# STM32N655 register map
File version: 1.0
CPU: CM55 r0p1, little endian, no MPU, FPU, vendor SysTick, 8 interrupt priority bits
Registers are 32-bit, read-write, reset 0x0 unless marked. A register's access mark holds for its fields unless they carry their own. Offsets are from the block's base; [hi:lo] are bit positions; {n}, {i} and the like mark numbered series.

## RCC (part 3 of 4) — Reset and clock control
Base 0x46028000
Same registers: RCC_S 0x56028000
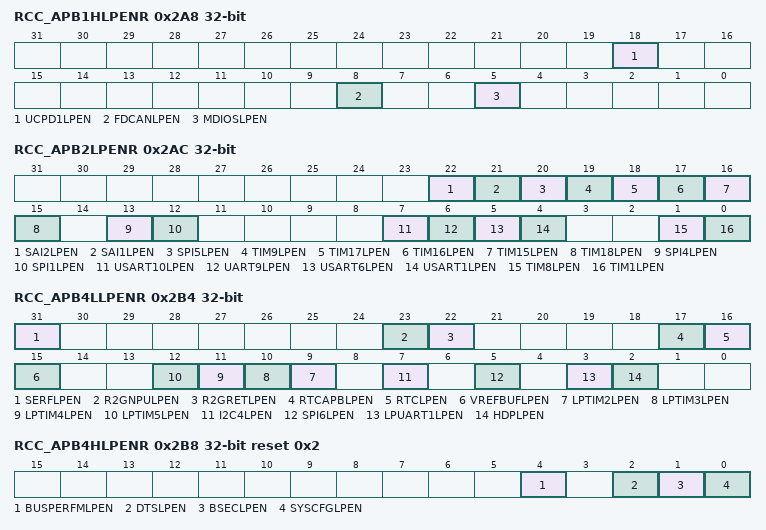
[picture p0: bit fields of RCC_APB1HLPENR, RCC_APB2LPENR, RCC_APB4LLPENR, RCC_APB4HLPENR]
0x2A8 RCC_APB1HLPENR — RCC APB1H Sleep enable register
  [18] UCPD1LPEN — UCPD1 sleep enable
    0=UCPD1 is disabled in Sleep mode (default after reset); 1=UCPD1 is enabled in Sleep mode
  [8] FDCANLPEN — FDCAN sleep enable
    0=FDCAN is disabled in Sleep mode (default after reset); 1=FDCAN is enabled in Sleep mode
  [5] MDIOSLPEN — MDIOS sleep enable
    0=MDIOS is disabled in Sleep mode (default after reset); 1=MDIOS is enabled in Sleep mode
0x2AC RCC_APB2LPENR — RCC APB2 Sleep enable register
  [22] SAI2LPEN — SAI2 sleep enable
    0=SAI2 is disabled in Sleep mode (default after reset); 1=SAI2 is enabled in Sleep mode
  [21] SAI1LPEN — SAI1 sleep enable
    0=SAI1 is disabled in Sleep mode (default after reset); 1=SAI1 is enabled in Sleep mode
  [20] SPI5LPEN — SPI5 sleep enable
    0=SPI5 is disabled in Sleep mode (default after reset); 1=SPI5 is enabled in Sleep mode
  [19] TIM9LPEN — TIM9 sleep enable
    0=TIM9 is disabled in Sleep mode (default after reset); 1=TIM9 is enabled in Sleep mode
  [18] TIM17LPEN — TIM17 sleep enable
    0=TIM17 is disabled in Sleep mode (default after reset); 1=TIM17 is enabled in Sleep mode
  [17] TIM16LPEN — TIM16 sleep enable
    0=TIM16 is disabled in Sleep mode (default after reset); 1=TIM16 is enabled in Sleep mode
  [16] TIM15LPEN — TIM15 sleep enable
    0=TIM15 is disabled in Sleep mode (default after reset); 1=TIM15 is enabled in Sleep mode
  [15] TIM18LPEN — TIM18 sleep enable
    0=TIM18 is disabled in Sleep mode (default after reset); 1=TIM18 is enabled in Sleep mode
  [13] SPI4LPEN — SPI4 sleep enable
    0=SPI4 is disabled in Sleep mode (default after reset); 1=SPI4 is enabled in Sleep mode
  [12] SPI1LPEN — SPI1 sleep enable
    0=SPI1 is disabled in Sleep mode (default after reset); 1=SPI1 is enabled in Sleep mode
  [7] USART10LPEN — USART10 sleep enable
    0=USART10 is disabled in Sleep mode (default after reset); 1=USART10 is enabled in Sleep mode
  [6] UART9LPEN — UART9 sleep enable
    0=UART9 is disabled in Sleep mode (default after reset); 1=UART9 is enabled in Sleep mode
  [5] USART6LPEN — USART6 sleep enable
    0=USART6 is disabled in Sleep mode (default after reset); 1=USART6 is enabled in Sleep mode
  [4] USART1LPEN — USART1 sleep enable
    0=USART1 is disabled in Sleep mode (default after reset); 1=USART1 is enabled in Sleep mode
  [1] TIM8LPEN — TIM8 sleep enable
    0=TIM8 is disabled in Sleep mode (default after reset); 1=TIM8 is enabled in Sleep mode
  [0] TIM1LPEN — TIM1 sleep enable
    0=TIM1 is disabled in Sleep mode (default after reset); 1=TIM1 is enabled in Sleep mode
0x2B0 RCC_APB3LPENR — RCC APB3 Sleep enable register
  [2] DFTLPEN — DFT sleep enable
    0=DFT is disabled in Sleep mode (default after reset); 1=DFT is enabled in Sleep mode
0x2B4 RCC_APB4LLPENR — RCC APB4L Sleep enable register
  [31] SERFLPEN — SERF sleep enable
    0=SERF is disabled in Sleep mode (default after reset); 1=SERF is enabled in Sleep mode
  [23] R2GNPULPEN — R2GNPU sleep enable
    0=R2GNPU is disabled in Sleep mode (default after reset); 1=R2GNPU is enabled in Sleep mode
  [22] R2GRETLPEN — R2GRET sleep enable
    0=R2GRET is disabled in Sleep mode (default after reset); 1=R2GRET is enabled in Sleep mode
  [17] RTCAPBLPEN — RTCAPB sleep enable
    0=RTCAPB is disabled in Sleep mode (default after reset); 1=RTCAPB is enabled in Sleep mode
  [16] RTCLPEN — RTC sleep enable
    0=RTC is disabled in Sleep mode (default after reset); 1=RTC is enabled in Sleep mode
  [15] VREFBUFLPEN — VREFBUF sleep enable
    0=VREFBUF is disabled in Sleep mode (default after reset); 1=VREFBUF is enabled in Sleep mode
  [n+7] LPTIM{n}LPEN (n=2..5) — LPTIM{n} sleep enable
    0=LPTIM{n} is disabled in Sleep mode (default after reset); 1=LPTIM{n} is enabled in Sleep mode
  [7] I2C4LPEN — I2C4 sleep enable
    0=I2C4 is disabled in Sleep mode (default after reset); 1=I2C4 is enabled in Sleep mode
  [5] SPI6LPEN — SPI6 sleep enable
    0=SPI6 is disabled in Sleep mode (default after reset); 1=SPI6 is enabled in Sleep mode
  [3] LPUART1LPEN — LPUART1 sleep enable
    0=LPUART1 is disabled in Sleep mode (default after reset); 1=LPUART1 is enabled in Sleep mode
  [2] HDPLPEN — HDP sleep enable
    0=HDP is disabled in Sleep mode (default after reset); 1=HDP is enabled in Sleep mode
0x2B8 RCC_APB4HLPENR reset 0x2 — RCC APB4H Sleep enable register
  [4] BUSPERFMLPEN — BUSPERFM sleep enable
    0=BUSPERFM is disabled in Sleep mode (default after reset); 1=BUSPERFM is enabled in Sleep mode
  [2] DTSLPEN — DTS sleep enable
    0=DTS is disabled in Sleep mode (default after reset); 1=DTS is enabled in Sleep mode
  [1] BSECLPEN — BSEC sleep enable
    0=BSEC is disabled in Sleep mode; 1=BSEC is enabled in Sleep mode (default after reset)
  [0] SYSCFGLPEN — SYSCFG sleep enable
    0=SYSCFG is disabled in Sleep mode (default after reset); 1=SYSCFG is enabled in Sleep mode
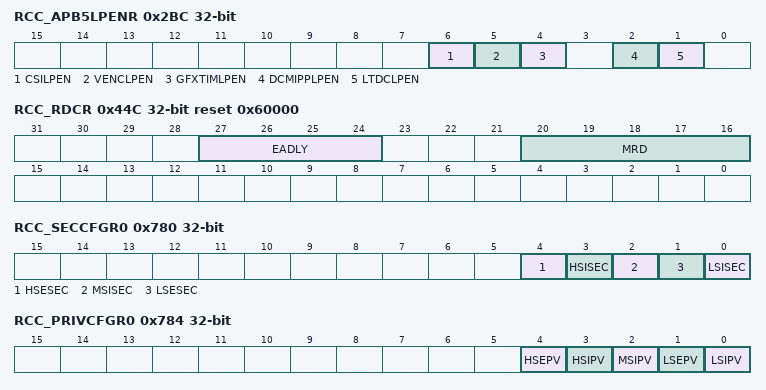
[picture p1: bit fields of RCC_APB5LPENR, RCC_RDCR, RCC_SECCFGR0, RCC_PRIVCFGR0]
0x2BC RCC_APB5LPENR — RCC APB5 Sleep enable register
  [6] CSILPEN — CSI sleep enable
    0=CSI is disabled in Sleep mode (default after reset); 1=CSI is enabled in Sleep mode
  [5] VENCLPEN — VENC sleep enable
    0=VENC is disabled in Sleep mode (default after reset); 1=VENC is enabled in Sleep mode
  [4] GFXTIMLPEN — GFXTIM sleep enable
    0=GFXTIM is disabled in Sleep mode (default after reset); 1=GFXTIM is enabled in Sleep mode
  [2] DCMIPPLPEN — DCMIPP sleep enable
    0=DCMIPP is disabled in Sleep mode (default after reset); 1=DCMIPP is enabled in Sleep mode
  [1] LTDCLPEN — LTDC sleep enable
    0=LTDC is disabled in Sleep mode (default after reset); 1=LTDC is enabled in Sleep mode
0x44C RCC_RDCR reset 0x60000 — RCC APB5 Sleep enable register
  [27:24] EADLY — BOOTROM sleep enable
    0=sysrstn low pulse duration is guaranteed by the pulse stretcher of the PAD. The RPCTL is bypassed (default after reset); 1=The guaranteed sysrstn low pulse duration is about 1 ms (1 x 32 lsi_ck cycles); 2=The guaranteed sysrstn low pulse duration is about 2 ms (2 x 32 lsi_ck cycles)
  [20:16] MRD — BOOTROM sleep enable
    0=No extra delay added by the BOOTROM; 1=100 us; 2=200 us; 3=500 us; 4=1 ms; 5=2 ms; 6=5 ms (default after reset); 7=10 ms; 8=20 ms; 9=50 ms; 10=100 ms; 11=200 ms; 12=500 ms; 13=1 s; 14=2 s; 15=5 s
0x780 RCC_SECCFGR0 — RCC oscillator secure configuration register0
  [4] HSESEC — Defines the secure protection of the HSE oscillator configuration bits.
    0=HSE configuration bits are accessible by non-secure software only (default after reset); 1=HSE configuration bits are accessible by secure software only
  [3] HSISEC — Defines the secure protection of the HSI oscillator configuration bits.
    0=HSI configuration bits are accessible by non-secure software only (default after reset); 1=HSI configuration bits are accessible by secure software only
  [2] MSISEC — Defines the secure protection of the MSI oscillator configuration bits.
    0=MSI configuration bits are accessible by non-secure software only (default after reset); 1=MSI configuration bits are accessible by secure software only
  [1] LSESEC — Defines the secure protection of the LSE oscillator configuration bits.
    0=LSE configuration bits are accessible by non-secure software only (default after reset); 1=LSE configuration bits are accessible by secure software only
  [0] LSISEC — Defines the secure protection of the LSI oscillator configuration bits.
    0=LSI configuration bits are accessible by non-secure software only (default after reset); 1=LSI configuration bits are accessible by secure software only
0x784 RCC_PRIVCFGR0 — RCC oscillator privilege configuration register0
  [4] HSEPV — Defines the privilege protection of the HSE oscillator configuration bits.
    0=HSE configuration bits are accessible by non-privilege software only (default after reset); 1=HSE configuration bits are accessible by privilege software only
  [3] HSIPV — Defines the privilege protection of the HSI oscillator configuration bits.
    0=HSI configuration bits are accessible by non-privilege software only (default after reset); 1=HSI configuration bits are accessible by privilege software only
  [2] MSIPV — Defines the privilege protection of the MSI oscillator configuration bits.
    0=MSI configuration bits are accessible by non-privilege software only (default after reset); 1=MSI configuration bits are accessible by privilege software only
  [1] LSEPV — Defines the privilege protection of the LSE oscillator configuration bits.
    0=LSE configuration bits are accessible by non-privilege software only (default after reset); 1=LSE configuration bits are accessible by privilege software only
  [0] LSIPV — Defines the privilege protection of the LSI oscillator configuration bits.
    0=LSI configuration bits are accessible by non-privilege software only (default after reset); 1=LSI configuration bits are accessible by privilege software only
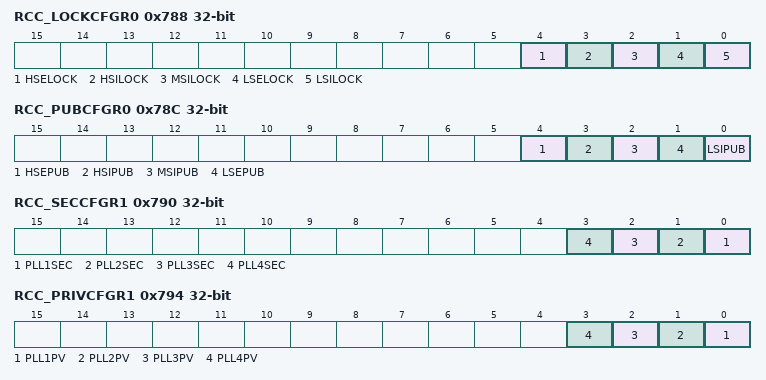
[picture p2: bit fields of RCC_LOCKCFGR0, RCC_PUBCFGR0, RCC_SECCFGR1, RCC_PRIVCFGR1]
0x788 RCC_LOCKCFGR0 wo — RCC oscillator lock configuration register0
  [4] HSELOCK — Defines the lock protection of the HSE oscillator configuration bits.
    0=HSE configuration bits are accessible by non-lock software only (default after reset); 1=HSE configuration bits are accessible by lock software only
  [3] HSILOCK — Defines the lock protection of the HSI oscillator configuration bits.
    0=HSI configuration bits are accessible by non-lock software only (default after reset); 1=HSI configuration bits are accessible by lock software only
  [2] MSILOCK — Defines the lock protection of the MSI oscillator configuration bits.
    0=MSI configuration bits are accessible by non-lock software only (default after reset); 1=MSI configuration bits are accessible by lock software only
  [1] LSELOCK — Defines the lock protection of the LSE oscillator configuration bits.
    0=LSE configuration bits are accessible by non-lock software only (default after reset); 1=LSE configuration bits are accessible by lock software only
  [0] LSILOCK — Defines the lock protection of the LSI oscillator configuration bits.
    0=LSI configuration bits are accessible by non-lock software only (default after reset); 1=LSI configuration bits are accessible by lock software only
0x78C RCC_PUBCFGR0 — RCC oscillator public configuration register0
  [4] HSEPUB — Defines the public protection of the HSE oscillator configuration bits.
    0=HSE configuration bits are accessible by non-public software only (default after reset); 1=HSE configuration bits are accessible by public software only
  [3] HSIPUB — Defines the public protection of the HSI oscillator configuration bits.
    0=HSI configuration bits are accessible by non-public software only (default after reset); 1=HSI configuration bits are accessible by public software only
  [2] MSIPUB — Defines the public protection of the MSI oscillator configuration bits.
    0=MSI configuration bits are accessible by non-public software only (default after reset); 1=MSI configuration bits are accessible by public software only
  [1] LSEPUB — Defines the public protection of the LSE oscillator configuration bits.
    0=LSE configuration bits are accessible by non-public software only (default after reset); 1=LSE configuration bits are accessible by public software only
  [0] LSIPUB — Defines the public protection of the LSI oscillator configuration bits.
    0=LSI configuration bits are accessible by non-public software only (default after reset); 1=LSI configuration bits are accessible by public software only
0x790 RCC_SECCFGR1 — RCC PLL secure configuration register1
  [n-1] PLL{n}SEC (n=1..4) — Defines the secure protection of the PLL{n} PLL configuration bits.
    0=PLL{n} configuration bits are accessible by non-secure software only (default after reset); 1=PLL{n} configuration bits are accessible by secure software only
0x794 RCC_PRIVCFGR1 — RCC PLL privilege configuration register1
  [n-1] PLL{n}PV (n=1..4) — Defines the privilege protection of the PLL{n} PLL configuration bits.
    0=PLL{n} configuration bits are accessible by non-privilege software only (default after reset); 1=PLL{n} configuration bits are accessible by privilege software only
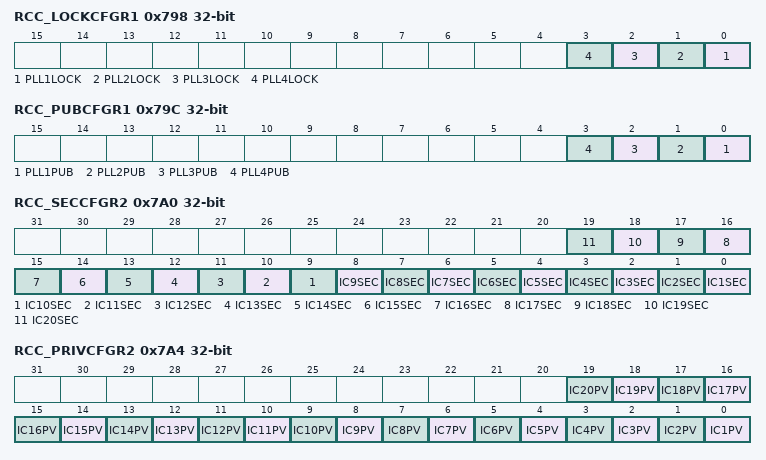
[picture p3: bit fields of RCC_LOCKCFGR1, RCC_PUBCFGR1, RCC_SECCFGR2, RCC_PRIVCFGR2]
0x798 RCC_LOCKCFGR1 wo — RCC PLL lock configuration register1
  [n-1] PLL{n}LOCK (n=1..4) — Defines the lock protection of the PLL{n} PLL configuration bits.
    0=PLL{n} configuration bits are accessible by non-lock software only (default after reset); 1=PLL{n} configuration bits are accessible by lock software only
0x79C RCC_PUBCFGR1 — RCC PLL public configuration register1
  [n-1] PLL{n}PUB (n=1..4) — Defines the public protection of the PLL{n} PLL configuration bits.
    0=PLL{n} configuration bits are accessible by non-public software only (default after reset); 1=PLL{n} configuration bits are accessible by public software only
0x7A0 RCC_SECCFGR2 — RCC divider secure configuration register2
  [n-1] IC{n}SEC (n=1..20) — Defines the secure protection of the IC{n} divider configuration bits.
    0=IC{n} configuration bits are accessible by non-secure software only (default after reset); 1=IC{n} configuration bits are accessible by secure software only
0x7A4 RCC_PRIVCFGR2 — RCC divider privilege configuration register2
  [n-1] IC{n}PV (n=1..20) — Defines the privilege protection of the IC{n} divider configuration bits.
    0=IC{n} configuration bits are accessible by non-privilege software only (default after reset); 1=IC{n} configuration bits are accessible by privilege software only
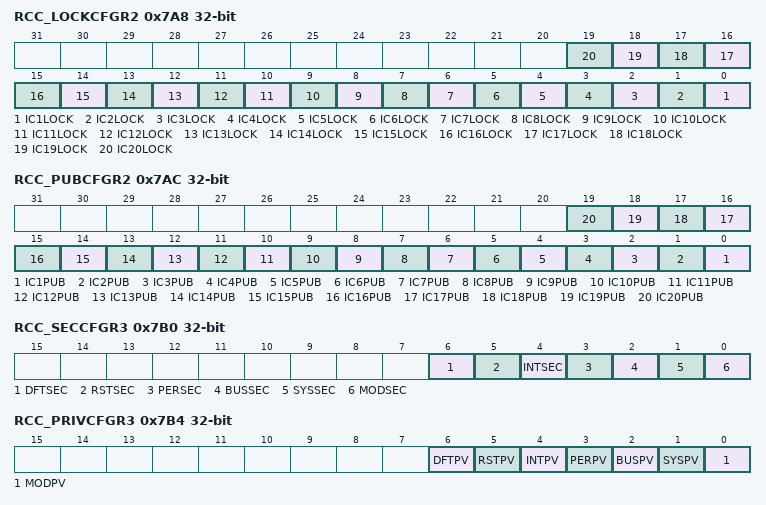
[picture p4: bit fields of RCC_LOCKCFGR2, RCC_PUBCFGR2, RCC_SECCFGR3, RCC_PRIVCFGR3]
0x7A8 RCC_LOCKCFGR2 wo — RCC divider lock configuration register2
  [n-1] IC{n}LOCK (n=1..20) — Defines the lock protection of the IC{n} divider configuration bits.
    0=IC{n} configuration bits are accessible by non-lock software only (default after reset); 1=IC{n} configuration bits are accessible by lock software only
0x7AC RCC_PUBCFGR2 — RCC divider public configuration register2
  [n-1] IC{n}PUB (n=1..20) — Defines the public protection of the IC{n} divider configuration bits.
    0=IC{n} configuration bits are accessible by non-public software only (default after reset); 1=IC{n} configuration bits are accessible by public software only
0x7B0 RCC_SECCFGR3 — RCC system secure configuration register3
  [6] DFTSEC — Defines the secure protection of the DFT system configuration bits.
    0=DFT configuration bits are accessible by non-secure software only (default after reset); 1=DFT configuration bits are accessible by secure software only
  [5] RSTSEC — Defines the secure protection of the RST system configuration bits.
    0=RST configuration bits are accessible by non-secure software only (default after reset); 1=RST configuration bits are accessible by secure software only
  [4] INTSEC — Defines the secure protection of the INT system configuration bits.
    0=INT configuration bits are accessible by non-secure software only (default after reset); 1=INT configuration bits are accessible by secure software only
  [3] PERSEC — Defines the secure protection of the PER system configuration bits.
    0=PER configuration bits are accessible by non-secure software only (default after reset); 1=PER configuration bits are accessible by secure software only
  [2] BUSSEC — Defines the secure protection of the BUS system configuration bits.
    0=BUS configuration bits are accessible by non-secure software only (default after reset); 1=BUS configuration bits are accessible by secure software only
  [1] SYSSEC — Defines the secure protection of the SYS system configuration bits.
    0=SYS configuration bits are accessible by non-secure software only (default after reset); 1=SYS configuration bits are accessible by secure software only
  [0] MODSEC — Defines the secure protection of the MOD system configuration bits.
    0=MOD configuration bits are accessible by non-secure software only (default after reset); 1=MOD configuration bits are accessible by secure software only
0x7B4 RCC_PRIVCFGR3 — RCC system privilege configuration register3
  [6] DFTPV — Defines the privilege protection of the DFT system configuration bits.
    0=DFT configuration bits are accessible by non-privilege software only (default after reset); 1=DFT configuration bits are accessible by privilege software only
  [5] RSTPV — Defines the privilege protection of the RST system configuration bits.
    0=RST configuration bits are accessible by non-privilege software only (default after reset); 1=RST configuration bits are accessible by privilege software only
  [4] INTPV — Defines the privilege protection of the INT system configuration bits.
    0=INT configuration bits are accessible by non-privilege software only (default after reset); 1=INT configuration bits are accessible by privilege software only
  [3] PERPV — Defines the privilege protection of the PER system configuration bits.
    0=PER configuration bits are accessible by non-privilege software only (default after reset); 1=PER configuration bits are accessible by privilege software only
  [2] BUSPV — Defines the privilege protection of the BUS system configuration bits.
    0=BUS configuration bits are accessible by non-privilege software only (default after reset); 1=BUS configuration bits are accessible by privilege software only
  [1] SYSPV — Defines the privilege protection of the SYS system configuration bits.
    0=SYS configuration bits are accessible by non-privilege software only (default after reset); 1=SYS configuration bits are accessible by privilege software only
  [0] MODPV — Defines the privilege protection of the MOD system configuration bits.
    0=MOD configuration bits are accessible by non-privilege software only (default after reset); 1=MOD configuration bits are accessible by privilege software only
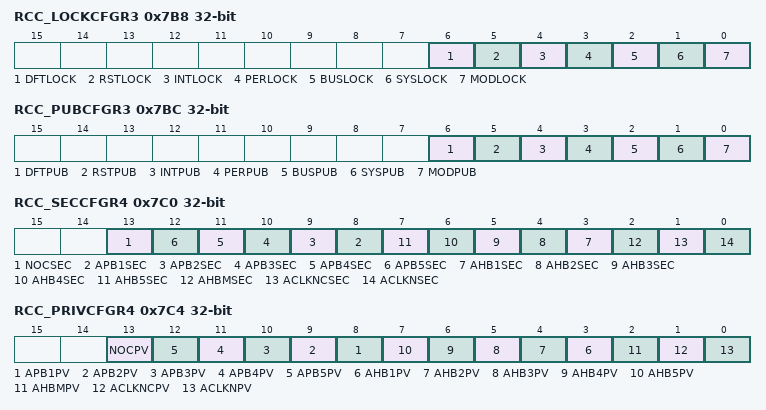
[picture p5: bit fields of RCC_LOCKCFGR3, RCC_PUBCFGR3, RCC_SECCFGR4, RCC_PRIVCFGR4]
0x7B8 RCC_LOCKCFGR3 wo — RCC system lock configuration register3
  [6] DFTLOCK — Defines the lock protection of the DFT system configuration bits.
    0=DFT configuration bits are accessible by non-lock software only (default after reset); 1=DFT configuration bits are accessible by lock software only
  [5] RSTLOCK — Defines the lock protection of the RST system configuration bits.
    0=RST configuration bits are accessible by non-lock software only (default after reset); 1=RST configuration bits are accessible by lock software only
  [4] INTLOCK — Defines the lock protection of the INT system configuration bits.
    0=INT configuration bits are accessible by non-lock software only (default after reset); 1=INT configuration bits are accessible by lock software only
  [3] PERLOCK — Defines the lock protection of the PER system configuration bits.
    0=PER configuration bits are accessible by non-lock software only (default after reset); 1=PER configuration bits are accessible by lock software only
  [2] BUSLOCK — Defines the lock protection of the BUS system configuration bits.
    0=BUS configuration bits are accessible by non-lock software only (default after reset); 1=BUS configuration bits are accessible by lock software only
  [1] SYSLOCK — Defines the lock protection of the SYS system configuration bits.
    0=SYS configuration bits are accessible by non-lock software only (default after reset); 1=SYS configuration bits are accessible by lock software only
  [0] MODLOCK — Defines the lock protection of the MOD system configuration bits.
    0=MOD configuration bits are accessible by non-lock software only (default after reset); 1=MOD configuration bits are accessible by lock software only
0x7BC RCC_PUBCFGR3 — RCC system public configuration register3
  [6] DFTPUB — Defines the public protection of the DFT system configuration bits.
    0=DFT configuration bits are accessible by non-public software only (default after reset); 1=DFT configuration bits are accessible by public software only
  [5] RSTPUB — Defines the public protection of the RST system configuration bits.
    0=RST configuration bits are accessible by non-public software only (default after reset); 1=RST configuration bits are accessible by public software only
  [4] INTPUB — Defines the public protection of the INT system configuration bits.
    0=INT configuration bits are accessible by non-public software only (default after reset); 1=INT configuration bits are accessible by public software only
  [3] PERPUB — Defines the public protection of the PER system configuration bits.
    0=PER configuration bits are accessible by non-public software only (default after reset); 1=PER configuration bits are accessible by public software only
  [2] BUSPUB — Defines the public protection of the BUS system configuration bits.
    0=BUS configuration bits are accessible by non-public software only (default after reset); 1=BUS configuration bits are accessible by public software only
  [1] SYSPUB — Defines the public protection of the SYS system configuration bits.
    0=SYS configuration bits are accessible by non-public software only (default after reset); 1=SYS configuration bits are accessible by public software only
  [0] MODPUB — Defines the public protection of the MOD system configuration bits.
    0=MOD configuration bits are accessible by non-public software only (default after reset); 1=MOD configuration bits are accessible by public software only
0x7C0 RCC_SECCFGR4 — RCC bus secure configuration register4
  [13] NOCSEC — Defines the secure protection of the NOC bus configuration bits.
    0=NOC configuration bits are accessible by non-secure software only (default after reset); 1=NOC configuration bits are accessible by secure software only
  [n+7] APB{n}SEC (n=1..5) — Defines the secure protection of the APB{n} bus configuration bits.
    0=APB{n} configuration bits are accessible by non-secure software only (default after reset); 1=APB{n} configuration bits are accessible by secure software only
  [n+2] AHB{n}SEC (n=1..5) — Defines the secure protection of the AHB{n} bus configuration bits.
    0=AHB{n} configuration bits are accessible by non-secure software only (default after reset); 1=AHB{n} configuration bits are accessible by secure software only
  [2] AHBMSEC — Defines the secure protection of the AHBM bus configuration bits.
    0=AHBM configuration bits are accessible by non-secure software only (default after reset); 1=AHBM configuration bits are accessible by secure software only
  [1] ACLKNCSEC — Defines the secure protection of the ACLKNC bus configuration bits.
    0=ACLKNC configuration bits are accessible by non-secure software only (default after reset); 1=ACLKNC configuration bits are accessible by secure software only
  [0] ACLKNSEC — Defines the secure protection of the ACLKN bus configuration bits.
    0=ACLKN configuration bits are accessible by non-secure software only (default after reset); 1=ACLKN configuration bits are accessible by secure software only
0x7C4 RCC_PRIVCFGR4 — RCC bus privilege configuration register4
  [13] NOCPV — Defines the privilege protection of the NOC bus configuration bits.
    0=NOC configuration bits are accessible by non-privilege software only (default after reset); 1=NOC configuration bits are accessible by privilege software only
  [n+7] APB{n}PV (n=1..5) — Defines the privilege protection of the APB{n} bus configuration bits.
    0=APB{n} configuration bits are accessible by non-privilege software only (default after reset); 1=APB{n} configuration bits are accessible by privilege software only
  [n+2] AHB{n}PV (n=1..5) — Defines the privilege protection of the AHB{n} bus configuration bits.
    0=AHB{n} configuration bits are accessible by non-privilege software only (default after reset); 1=AHB{n} configuration bits are accessible by privilege software only
  [2] AHBMPV — Defines the privilege protection of the AHBM bus configuration bits.
    0=AHBM configuration bits are accessible by non-privilege software only (default after reset); 1=AHBM configuration bits are accessible by privilege software only
  [1] ACLKNCPV — Defines the privilege protection of the ACLKNC bus configuration bits.
    0=ACLKNC configuration bits are accessible by non-privilege software only (default after reset); 1=ACLKNC configuration bits are accessible by privilege software only
  [0] ACLKNPV — Defines the privilege protection of the ACLKN bus configuration bits.
    0=ACLKN configuration bits are accessible by non-privilege software only (default after reset); 1=ACLKN configuration bits are accessible by privilege software only
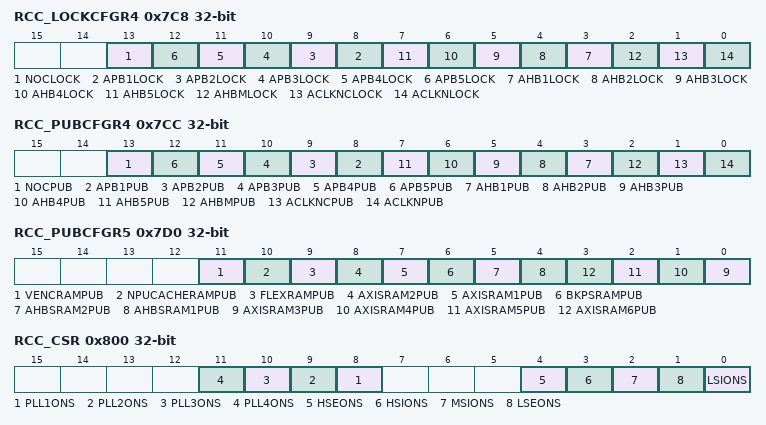
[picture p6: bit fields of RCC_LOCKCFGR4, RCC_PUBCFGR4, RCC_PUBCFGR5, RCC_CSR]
0x7C8 RCC_LOCKCFGR4 wo — RCC bus lock configuration register4
  [13] NOCLOCK — Defines the lock protection of the NOC bus configuration bits.
    0=NOC configuration bits are accessible by non-lock software only (default after reset); 1=NOC configuration bits are accessible by lock software only
  [n+7] APB{n}LOCK (n=1..5) — Defines the lock protection of the APB{n} bus configuration bits.
    0=APB{n} configuration bits are accessible by non-lock software only (default after reset); 1=APB{n} configuration bits are accessible by lock software only
  [n+2] AHB{n}LOCK (n=1..5) — Defines the lock protection of the AHB{n} bus configuration bits.
    0=AHB{n} configuration bits are accessible by non-lock software only (default after reset); 1=AHB{n} configuration bits are accessible by lock software only
  [2] AHBMLOCK — Defines the lock protection of the AHBM bus configuration bits.
    0=AHBM configuration bits are accessible by non-lock software only (default after reset); 1=AHBM configuration bits are accessible by lock software only
  [1] ACLKNCLOCK — Defines the lock protection of the ACLKNC bus configuration bits.
    0=ACLKNC configuration bits are accessible by non-lock software only (default after reset); 1=ACLKNC configuration bits are accessible by lock software only
  [0] ACLKNLOCK — Defines the lock protection of the ACLKN bus configuration bits.
    0=ACLKN configuration bits are accessible by non-lock software only (default after reset); 1=ACLKN configuration bits are accessible by lock software only
0x7CC RCC_PUBCFGR4 — RCC bus public configuration register4
  [13] NOCPUB — Defines the public protection of the NOC bus configuration bits.
    0=NOC configuration bits are accessible by non-public software only (default after reset); 1=NOC configuration bits are accessible by public software only
  [n+7] APB{n}PUB (n=1..5) — Defines the public protection of the APB{n} bus configuration bits.
    0=APB{n} configuration bits are accessible by non-public software only (default after reset); 1=APB{n} configuration bits are accessible by public software only
  [n+2] AHB{n}PUB (n=1..5) — Defines the public protection of the AHB{n} bus configuration bits.
    0=AHB{n} configuration bits are accessible by non-public software only (default after reset); 1=AHB{n} configuration bits are accessible by public software only
  [2] AHBMPUB — Defines the public protection of the AHBM bus configuration bits.
    0=AHBM configuration bits are accessible by non-public software only (default after reset); 1=AHBM configuration bits are accessible by public software only
  [1] ACLKNCPUB — Defines the public protection of the ACLKNC bus configuration bits.
    0=ACLKNC configuration bits are accessible by non-public software only (default after reset); 1=ACLKNC configuration bits are accessible by public software only
  [0] ACLKNPUB — Defines the public protection of the ACLKN bus configuration bits.
    0=ACLKN configuration bits are accessible by non-public software only (default after reset); 1=ACLKN configuration bits are accessible by public software only
0x7D0 RCC_PUBCFGR5 — RCC bus public configuration register4
  [11] VENCRAMPUB — Defines the public protection of the VENCRAM bus configuration bits.
    0=VENCRAM configuration bits are accessible by non-public software only (default after reset); 1=VENCRAM configuration bits are accessible by public software only
  [10] NPUCACHERAMPUB — Defines the public protection of the NPUCACHERAM bus configuration bits.
    0=NPUCACHERAM configuration bits are accessible by non-public software only (default after reset); 1=NPUCACHERAM configuration bits are accessible by public software only
  [9] FLEXRAMPUB — Defines the public protection of the FLEXRAM bus configuration bits.
    0=FLEXRAM configuration bits are accessible by non-public software only (default after reset); 1=FLEXRAM configuration bits are accessible by public software only
  [8] AXISRAM2PUB — Defines the public protection of the AXISRAM2 bus configuration bits.
    0=AXISRAM2 configuration bits are accessible by non-public software only (default after reset); 1=AXISRAM2 configuration bits are accessible by public software only
  [7] AXISRAM1PUB — Defines the public protection of the AXISRAM1 bus configuration bits.
    0=AXISRAM1 configuration bits are accessible by non-public software only (default after reset); 1=AXISRAM1 configuration bits are accessible by public software only
  [6] BKPSRAMPUB — Defines the public protection of the BKPSRAM bus configuration bits.
    0=BKPSRAM configuration bits are accessible by non-public software only (default after reset); 1=BKPSRAM configuration bits are accessible by public software only
  [5] AHBSRAM2PUB — Defines the public protection of the AHBSRAM2 bus configuration bits.
    0=AHBSRAM2 configuration bits are accessible by non-public software only (default after reset); 1=AHBSRAM2 configuration bits are accessible by public software only
  [4] AHBSRAM1PUB — Defines the public protection of the AHBSRAM1 bus configuration bits.
    0=AHBSRAM1 configuration bits are accessible by non-public software only (default after reset); 1=AHBSRAM1 configuration bits are accessible by public software only
  [n-3] AXISRAM{n}PUB (n=3..6) — Defines the public protection of the AXISRAM{n} bus configuration bits.
    0=AXISRAM{n} configuration bits are accessible by non-public software only (default after reset); 1=AXISRAM{n} configuration bits are accessible by public software only
0x800 RCC_CSR wo — RCC control set register
  [n+7] PLL{n}ONS (n=1..4) — PLL{n} oscillator enable in Run/Sleep mode.
  [4] HSEONS — HSE oscillator enable in Run/Sleep mode.
  [3] HSIONS — HSI oscillator enable in Run/Sleep mode.
  [2] MSIONS — MSI oscillator enable in Run/Sleep mode.
  [1] LSEONS — LSE oscillator enable in Run/Sleep mode.
  [0] LSIONS — LSI oscillator enable in Run/Sleep mode.
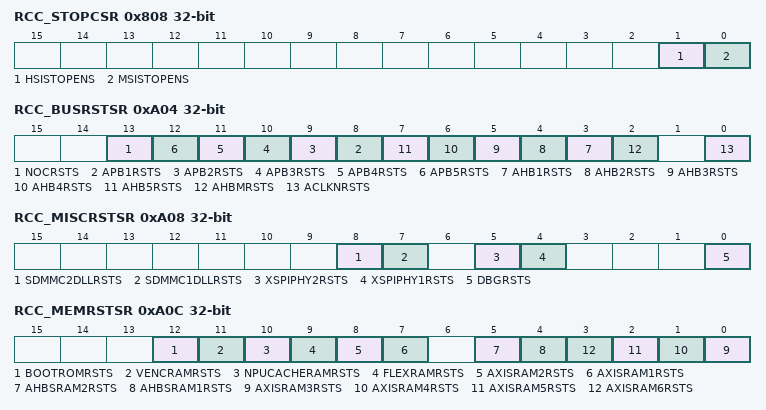
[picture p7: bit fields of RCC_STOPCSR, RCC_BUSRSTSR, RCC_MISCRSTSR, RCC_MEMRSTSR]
0x808 RCC_STOPCSR wo — RCC Stop configuration register
  [1] HSISTOPENS, [0] MSISTOPENS
0xA04 RCC_BUSRSTSR wo — RCC bus reset set register
  [13] NOCRSTS — NOC reset
  [n+7] APB{n}RSTS (n=1..5) — APB{n} reset
  [n+2] AHB{n}RSTS (n=1..5) — AHB{n} reset
  [2] AHBMRSTS — AHBM reset
  [0] ACLKNRSTS — ACLKN reset
0xA08 RCC_MISCRSTSR wo — RCC miscellaneous reset register
  [8] SDMMC2DLLRSTS — SDMMC2DLL reset
  [7] SDMMC1DLLRSTS — SDMMC1DLL reset
  [5] XSPIPHY2RSTS — XSPIPHY2 reset
  [4] XSPIPHY1RSTS — XSPIPHY1 reset
  [0] DBGRSTS — DBG reset
0xA0C RCC_MEMRSTSR wo — RCC memory reset register
  [12] BOOTROMRSTS — BOOTROM reset
  [11] VENCRAMRSTS — VENCRAM reset
  [10] NPUCACHERAMRSTS — NPUCACHERAM reset
  [9] FLEXRAMRSTS — FLEXRAM reset
  [8] AXISRAM2RSTS — AXISRAM2 reset
  [7] AXISRAM1RSTS — AXISRAM1 reset
  [5] AHBSRAM2RSTS — AHBSRAM2 reset
  [4] AHBSRAM1RSTS — AHBSRAM1 reset
  [n-3] AXISRAM{n}RSTS (n=3..6) — AXISRAM{n} reset
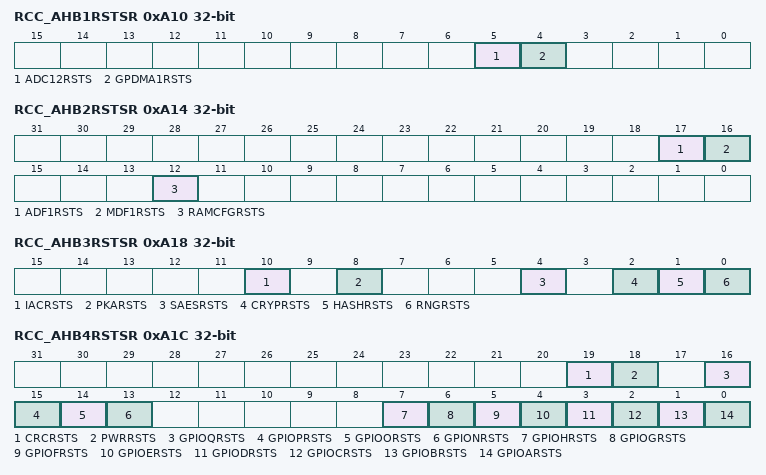
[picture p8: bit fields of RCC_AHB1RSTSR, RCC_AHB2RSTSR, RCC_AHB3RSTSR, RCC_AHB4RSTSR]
0xA10 RCC_AHB1RSTSR wo — RCC AHB1 reset register
  [5] ADC12RSTS — ADC12 reset
  [4] GPDMA1RSTS — GPDMA1 reset
0xA14 RCC_AHB2RSTSR wo — RCC AHB2 reset register
  [17] ADF1RSTS — ADF1 reset
  [16] MDF1RSTS — MDF1 reset
  [12] RAMCFGRSTS — RAMCFG reset
0xA18 RCC_AHB3RSTSR wo — RCC AHB3 reset register
  [10] IACRSTS — IAC reset
  [8] PKARSTS — PKA reset
  [4] SAESRSTS — SAES reset
  [2] CRYPRSTS — CRYP reset
  [1] HASHRSTS — HASH reset
  [0] RNGRSTS — RNG reset
0xA1C RCC_AHB4RSTSR wo — RCC AHB4 reset register
  [19] CRCRSTS — CRC reset
  [18] PWRRSTS — PWR reset
  [16] GPIOQRSTS — GPIOQ reset
  [15] GPIOPRSTS — GPIOP reset
  [14] GPIOORSTS — GPIOO reset
  [13] GPIONRSTS — GPION reset
  [7] GPIOHRSTS — GPIOH reset
  [6] GPIOGRSTS — GPIOG reset
  [5] GPIOFRSTS — GPIOF reset
  [4] GPIOERSTS — GPIOE reset
  [3] GPIODRSTS — GPIOD reset
  [2] GPIOCRSTS — GPIOC reset
  [1] GPIOBRSTS — GPIOB reset
  [0] GPIOARSTS — GPIOA reset
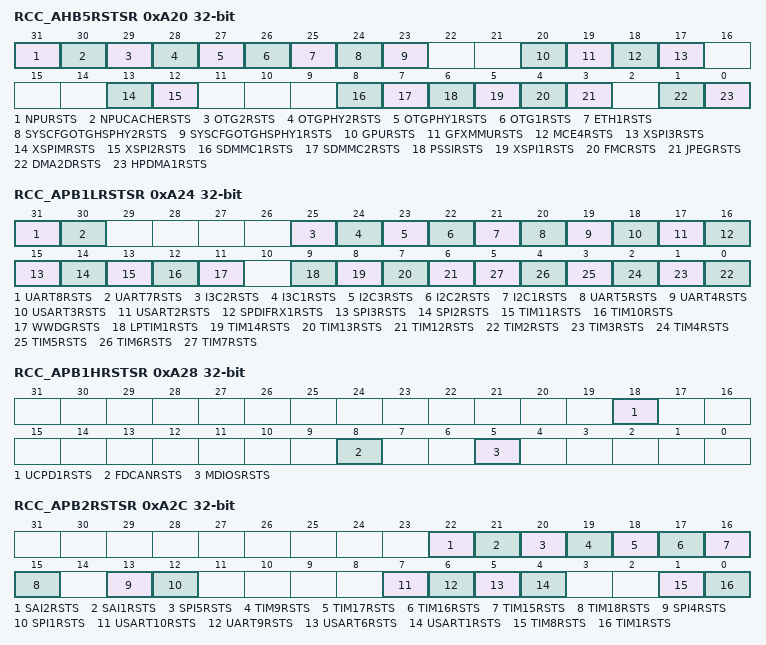
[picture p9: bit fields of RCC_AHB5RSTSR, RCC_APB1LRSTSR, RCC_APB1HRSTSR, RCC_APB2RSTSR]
0xA20 RCC_AHB5RSTSR wo — RCC AHB5 reset register
  [31] NPURSTS — NPU reset
  [30] NPUCACHERSTS — NPUCACHE reset
  [29] OTG2RSTS — OTG2 reset
  [28] OTGPHY2RSTS — OTGPHY2 reset
  [27] OTGPHY1RSTS — OTGPHY1 reset
  [26] OTG1RSTS — OTG1 reset
  [25] ETH1RSTS — ETH1 reset
  [24] SYSCFGOTGHSPHY2RSTS — SYSCFGOTGHSPHY2 reset
  [23] SYSCFGOTGHSPHY1RSTS — SYSCFGOTGHSPHY1 reset
  [20] GPURSTS — GPU reset
  [19] GFXMMURSTS — GFXMMU reset
  [18] MCE4RSTS — MCE4 reset
  [17] XSPI3RSTS — XSPI3 reset
  [13] XSPIMRSTS — XSPIM reset
  [12] XSPI2RSTS — XSPI2 reset
  [8] SDMMC1RSTS — SDMMC1 reset
  [7] SDMMC2RSTS — SDMMC2 reset
  [6] PSSIRSTS — PSSI reset
  [5] XSPI1RSTS — XSPI1 reset
  [4] FMCRSTS — FMC reset
  [3] JPEGRSTS — JPEG reset
  [1] DMA2DRSTS — DMA2D reset
  [0] HPDMA1RSTS — HPDMA1 reset
0xA24 RCC_APB1LRSTSR wo — RCC APB1L reset register
  [31] UART8RSTS — UART8 reset
  [30] UART7RSTS — UART7 reset
  [25] I3C2RSTS — I3C2 reset
  [24] I3C1RSTS — I3C1 reset
  [23] I2C3RSTS — I2C3 reset
  [22] I2C2RSTS — I2C2 reset
  [21] I2C1RSTS — I2C1 reset
  [20] UART5RSTS — UART5 reset
  [19] UART4RSTS — UART4 reset
  [18] USART3RSTS — USART3 reset
  [17] USART2RSTS — USART2 reset
  [16] SPDIFRX1RSTS — SPDIFRX1 reset
  [15] SPI3RSTS — SPI3 reset
  [14] SPI2RSTS — SPI2 reset
  [13] TIM11RSTS — TIM11 reset
  [12] TIM10RSTS — TIM10 reset
  [11] WWDGRSTS — WWDG reset
  [9] LPTIM1RSTS — LPTIM1 reset
  [8] TIM14RSTS — TIM14 reset
  [7] TIM13RSTS — TIM13 reset
  [6] TIM12RSTS — TIM12 reset
  [n-2] TIM{n}RSTS (n=2..7) — TIM{n} reset
0xA28 RCC_APB1HRSTSR wo — RCC APB1H reset register
  [18] UCPD1RSTS — UCPD1 reset
  [8] FDCANRSTS — FDCAN reset
  [5] MDIOSRSTS — MDIOS reset
0xA2C RCC_APB2RSTSR wo — RCC APB2 reset register
  [22] SAI2RSTS — SAI2 reset
  [21] SAI1RSTS — SAI1 reset
  [20] SPI5RSTS — SPI5 reset
  [19] TIM9RSTS — TIM9 reset
  [18] TIM17RSTS — TIM17 reset
  [17] TIM16RSTS — TIM16 reset
  [16] TIM15RSTS — TIM15 reset
  [15] TIM18RSTS — TIM18 reset
  [13] SPI4RSTS — SPI4 reset
  [12] SPI1RSTS — SPI1 reset
  [7] USART10RSTS — USART10 reset
  [6] UART9RSTS — UART9 reset
  [5] USART6RSTS — USART6 reset
  [4] USART1RSTS — USART1 reset
  [1] TIM8RSTS — TIM8 reset
  [0] TIM1RSTS — TIM1 reset
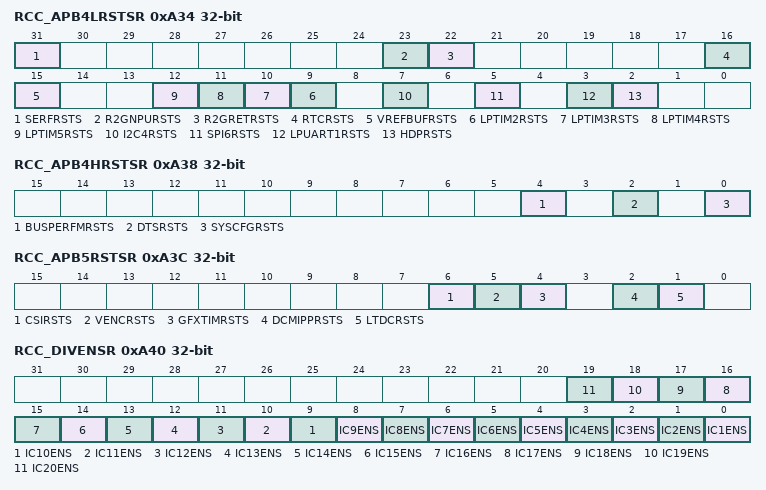
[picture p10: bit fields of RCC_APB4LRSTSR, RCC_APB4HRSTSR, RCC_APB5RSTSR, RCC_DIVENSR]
0xA34 RCC_APB4LRSTSR wo — RCC APB4L reset register
  [31] SERFRSTS — SERF reset
  [23] R2GNPURSTS — R2GNPU reset
  [22] R2GRETRSTS — R2GRET reset
  [16] RTCRSTS — RTC reset
  [15] VREFBUFRSTS — VREFBUF reset
  [n+7] LPTIM{n}RSTS (n=2..5) — LPTIM{n} reset
  [7] I2C4RSTS — I2C4 reset
  [5] SPI6RSTS — SPI6 reset
  [3] LPUART1RSTS — LPUART1 reset
  [2] HDPRSTS — HDP reset
0xA38 RCC_APB4HRSTSR wo — RCC APB4H reset register
  [4] BUSPERFMRSTS — BUSPERFM reset
  [2] DTSRSTS — DTS reset
  [0] SYSCFGRSTS — SYSCFG reset
0xA3C RCC_APB5RSTSR wo — RCC APB5 reset register
  [6] CSIRSTS — CSI reset
  [5] VENCRSTS — VENC reset
  [4] GFXTIMRSTS — GFXTIM reset
  [2] DCMIPPRSTS — DCMIPP reset
  [1] LTDCRSTS — LTDC reset
0xA40 RCC_DIVENSR wo — RCC Divider enable register
  [n-1] IC{n}ENS (n=1..20) — IC{n} enable
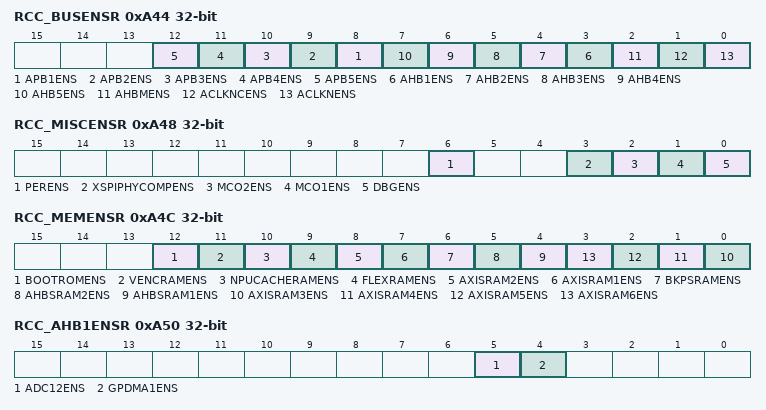
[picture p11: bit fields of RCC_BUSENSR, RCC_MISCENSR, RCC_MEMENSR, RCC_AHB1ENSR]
0xA44 RCC_BUSENSR wo — RCC bus enable register
  [n+7] APB{n}ENS (n=1..5) — APB{n} enable
  [n+2] AHB{n}ENS (n=1..5) — AHB{n} enable
  [2] AHBMENS — AHBM enable
  [1] ACLKNCENS — ACLKNC enable
  [0] ACLKNENS — ACLKN enable
0xA48 RCC_MISCENSR wo — RCC miscellaneous enable register
  [6] PERENS — PER enable
  [3] XSPIPHYCOMPENS — XSPIPHYCOMP enable
  [2] MCO2ENS — MCO2 enable
  [1] MCO1ENS — MCO1 enable
  [0] DBGENS — DBG enable
0xA4C RCC_MEMENSR wo — RCC memory enable register
  [12] BOOTROMENS — BOOTROM enable
  [11] VENCRAMENS — VENCRAM enable
  [10] NPUCACHERAMENS — NPUCACHERAM enable
  [9] FLEXRAMENS — FLEXRAM enable
  [8] AXISRAM2ENS — AXISRAM2 enable
  [7] AXISRAM1ENS — AXISRAM1 enable
  [6] BKPSRAMENS — BKPSRAM enable
  [5] AHBSRAM2ENS — AHBSRAM2 enable
  [4] AHBSRAM1ENS — AHBSRAM1 enable
  [n-3] AXISRAM{n}ENS (n=3..6) — AXISRAM{n} enable
0xA50 RCC_AHB1ENSR wo — RCC AHB1 enable register
  [5] ADC12ENS — ADC12 enable
  [4] GPDMA1ENS — GPDMA1 enable
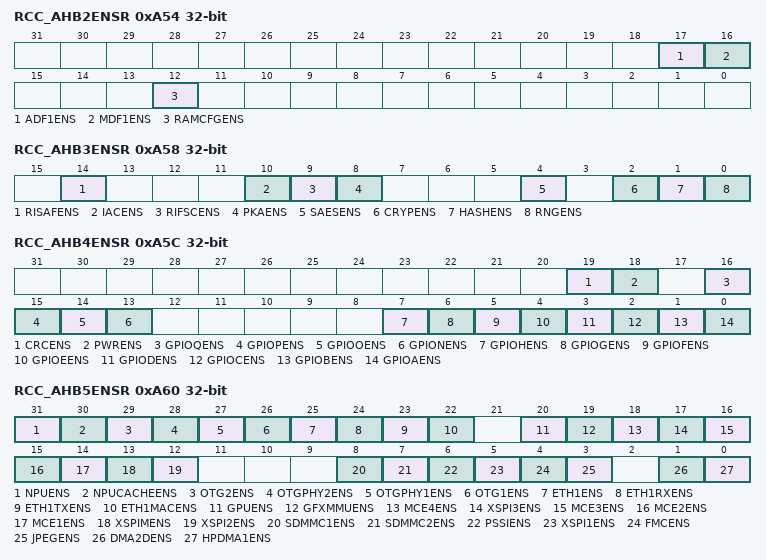
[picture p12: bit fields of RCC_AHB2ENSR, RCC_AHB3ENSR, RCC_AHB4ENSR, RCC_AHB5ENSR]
0xA54 RCC_AHB2ENSR wo — RCC AHB2 enable register
  [17] ADF1ENS — ADF1 enable
  [16] MDF1ENS — MDF1 enable
  [12] RAMCFGENS — RAMCFG enable
0xA58 RCC_AHB3ENSR wo — RCC AHB3 enable register
  [14] RISAFENS — RISAF enable
  [10] IACENS — IAC enable
  [9] RIFSCENS — RIFSC enable
  [8] PKAENS — PKA enable
  [4] SAESENS — SAES enable
  [2] CRYPENS — CRYP enable
  [1] HASHENS — HASH enable
  [0] RNGENS — RNG enable
0xA5C RCC_AHB4ENSR wo — RCC AHB4 enable register
  [19] CRCENS — CRC enable
  [18] PWRENS — PWR enable
  [16] GPIOQENS — GPIOQ enable
  [15] GPIOPENS — GPIOP enable
  [14] GPIOOENS — GPIOO enable
  [13] GPIONENS — GPION enable
  [7] GPIOHENS — GPIOH enable
  [6] GPIOGENS — GPIOG enable
  [5] GPIOFENS — GPIOF enable
  [4] GPIOEENS — GPIOE enable
  [3] GPIODENS — GPIOD enable
  [2] GPIOCENS — GPIOC enable
  [1] GPIOBENS — GPIOB enable
  [0] GPIOAENS — GPIOA enable
0xA60 RCC_AHB5ENSR wo — RCC AHB5 enable register
  [31] NPUENS — NPU enable
  [30] NPUCACHEENS — NPUCACHE enable
  [29] OTG2ENS — OTG2 enable
  [28] OTGPHY2ENS — OTGPHY2 enable
  [27] OTGPHY1ENS — OTGPHY1 enable
  [26] OTG1ENS — OTG1 enable
  [25] ETH1ENS — ETH1 enable
  [24] ETH1RXENS — ETH1RX enable
  [23] ETH1TXENS — ETH1TX enable
  [22] ETH1MACENS — ETH1MAC enable
  [20] GPUENS — GPU enable
  [19] GFXMMUENS — GFXMMU enable
  [18] MCE4ENS — MCE4 enable
  [17] XSPI3ENS — XSPI3 enable
  [16] MCE3ENS — MCE3 enable
  [15] MCE2ENS — MCE2 enable
  [14] MCE1ENS — MCE1 enable
  [13] XSPIMENS — XSPIM enable
  [12] XSPI2ENS — XSPI2 enable
  [8] SDMMC1ENS — SDMMC1 enable
  [7] SDMMC2ENS — SDMMC2 enable
  [6] PSSIENS — PSSI enable
  [5] XSPI1ENS — XSPI1 enable
  [4] FMCENS — FMC enable
  [3] JPEGENS — JPEG enable
  [1] DMA2DENS — DMA2D enable
  [0] HPDMA1ENS — HPDMA1 enable
